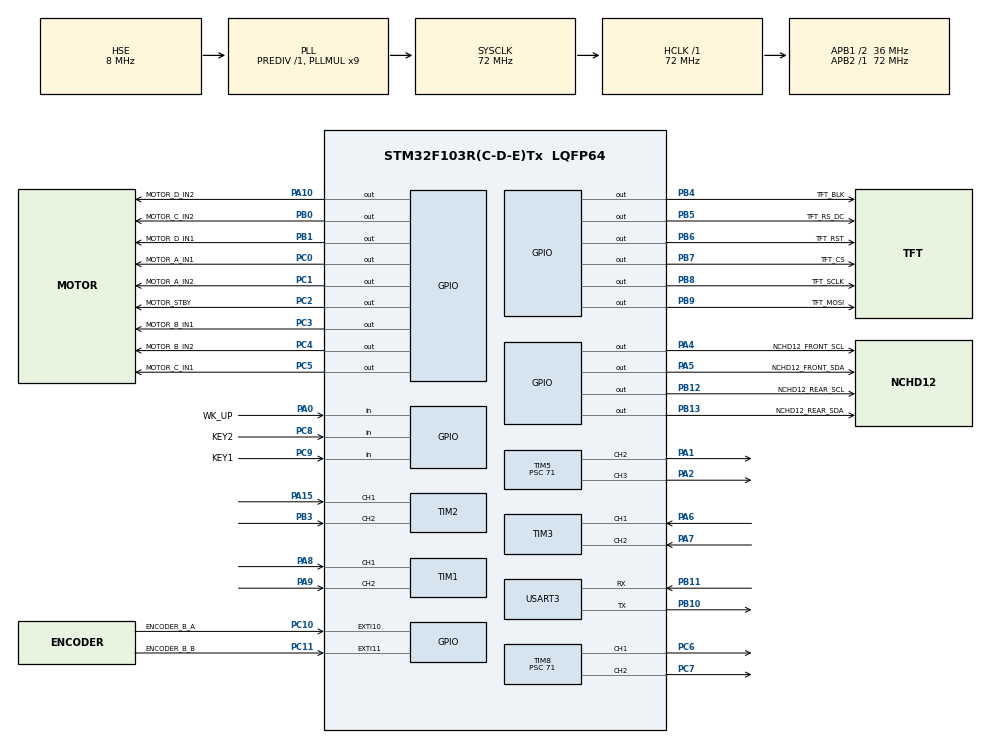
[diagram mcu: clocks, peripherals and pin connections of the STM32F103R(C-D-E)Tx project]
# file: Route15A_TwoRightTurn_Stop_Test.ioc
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Mcu.Family=STM32F1
Mcu.Name=STM32F103R(C-D-E)Tx
Mcu.Package=LQFP64
NVIC.EXTI15_10_IRQn=true\:5\:0\:false\:false\:true\:true\:true\:true
NVIC.PriorityGroup=NVIC_PRIORITYGROUP_4
PA0-WKUP.GPIO_Label=WK_UP
PA0-WKUP.GPIO_PuPd=GPIO_PULLDOWN
PA0-WKUP.Signal=GPIO_Input
PA1.Signal=S_TIM5_CH2
PA4.GPIO_Label=NCHD12_FRONT_SCL
PA4.Signal=GPIO_Output
PA5.GPIO_Label=NCHD12_FRONT_SDA
PA5.Signal=GPIO_Output
PA10.GPIO_Label=MOTOR_D_IN2
PA10.Signal=GPIO_Output
PA13.Mode=Serial_Wire
PA13.Signal=SYS_JTMS-SWDIO
PA14.Mode=Serial_Wire
PA14.Signal=SYS_JTCK-SWCLK
PA15.Signal=S_TIM2_CH1_ETR
PA2.Signal=S_TIM5_CH3
PA6.Signal=S_TIM3_CH1
PA7.Signal=S_TIM3_CH2
PA8.Signal=S_TIM1_CH1
PA9.Signal=S_TIM1_CH2
PB0.GPIO_Label=MOTOR_C_IN2
PB0.Signal=GPIO_Output
PB1.GPIO_Label=MOTOR_D_IN1
PB1.Signal=GPIO_Output
PB4.GPIO_Label=TFT_BLK
PB4.Signal=GPIO_Output
PB5.GPIO_Label=TFT_RS_DC
PB5.Signal=GPIO_Output
PB6.GPIO_Label=TFT_RST
PB6.Signal=GPIO_Output
PB7.GPIO_Label=TFT_CS
PB7.Signal=GPIO_Output
PB10.Mode=Asynchronous
PB10.Signal=USART3_TX
PB11.Mode=Asynchronous
PB11.Signal=USART3_RX
PB12.GPIO_Label=NCHD12_REAR_SCL
PB12.Signal=GPIO_Output
PB13.GPIO_Label=NCHD12_REAR_SDA
PB13.Signal=GPIO_Output
PB3.Signal=S_TIM2_CH2
PB8.GPIO_Label=TFT_SCLK
PB8.Signal=GPIO_Output
PB9.GPIO_Label=TFT_MOSI
PB9.Signal=GPIO_Output
PC10.GPIO_Label=ENCODER_B_A
PC10.GPIO_PuPd=GPIO_NOPULL
PC10.Signal=GPXTI10
PC11.GPIO_Label=ENCODER_B_B
PC11.GPIO_PuPd=GPIO_NOPULL
PC11.Signal=GPXTI11
PC0.GPIO_Label=MOTOR_A_IN1
PC0.Signal=GPIO_Output
PC1.GPIO_Label=MOTOR_A_IN2
PC1.Signal=GPIO_Output
PC2.GPIO_Label=MOTOR_STBY
PC2.Signal=GPIO_Output
PC3.GPIO_Label=MOTOR_B_IN1
PC3.Signal=GPIO_Output
PC4.GPIO_Label=MOTOR_B_IN2
PC4.Signal=GPIO_Output
PC5.GPIO_Label=MOTOR_C_IN1
PC5.Signal=GPIO_Output
PC6.Signal=S_TIM8_CH1
PC7.Signal=S_TIM8_CH2
PC8.GPIO_Label=KEY2
PC8.GPIO_PuPd=GPIO_PULLUP
PC8.Signal=GPIO_Input
PC9.GPIO_Label=KEY1
PC9.GPIO_PuPd=GPIO_PULLUP
PC9.Signal=GPIO_Input
PD0-OSC_IN.Mode=HSE-External-Oscillator
PD0-OSC_IN.Signal=RCC_OSC_IN
PD1-OSC_OUT.Mode=HSE-External-Oscillator
PD1-OSC_OUT.Signal=RCC_OSC_OUT
ProjectManager.HeapSize=0x200
ProjectManager.StackSize=0x400
ProjectManager.TargetToolchain=MDK-ARM V5.32
RCC.AHBFreq_Value=72000000
RCC.APB1CLKDivider=RCC_HCLK_DIV2
RCC.APB1Freq_Value=36000000
RCC.APB1TimFreq_Value=72000000
RCC.APB2Freq_Value=72000000
RCC.APB2TimFreq_Value=72000000
RCC.HCLKFreq_Value=72000000
RCC.PLLMUL=RCC_PLL_MUL9
RCC.PLLSourceVirtual=RCC_PLLSOURCE_HSE
RCC.SYSCLKFreq_VALUE=72000000
RCC.SYSCLKSource=RCC_SYSCLKSOURCE_PLLCLK
RCC.USBFreq_Value=72000000
SH.S_TIM1_CH1.0=TIM1_CH1,Encoder_Interface
SH.S_TIM1_CH2.0=TIM1_CH2,Encoder_Interface
SH.S_TIM2_CH1_ETR.0=TIM2_CH1,Encoder_Interface
SH.S_TIM2_CH2.0=TIM2_CH2,Encoder_Interface
SH.S_TIM3_CH1.0=TIM3_CH1,Encoder_Interface
SH.S_TIM3_CH2.0=TIM3_CH2,Encoder_Interface
SH.S_TIM5_CH2.0=TIM5_CH2,PWM Generation2 CH2
SH.S_TIM5_CH3.0=TIM5_CH3,PWM Generation3 CH3
SH.S_TIM8_CH1.0=TIM8_CH1,PWM Generation1 CH1
SH.S_TIM8_CH2.0=TIM8_CH2,PWM Generation2 CH2
TIM1.EncoderMode=TIM_ENCODERMODE_TI12
TIM2.EncoderMode=TIM_ENCODERMODE_TI12
TIM3.EncoderMode=TIM_ENCODERMODE_TI12
TIM5.AutoReloadPreload=TIM_AUTORELOAD_PRELOAD_ENABLE
TIM5.Channel-PWM\ Generation2\ CH2=TIM_CHANNEL_2
TIM5.Channel-PWM\ Generation3\ CH3=TIM_CHANNEL_3
TIM5.Period=999
TIM5.Prescaler=71
TIM8.AutoReloadPreload=TIM_AUTORELOAD_PRELOAD_ENABLE
TIM8.Channel-PWM\ Generation1\ CH1=TIM_CHANNEL_1
TIM8.Channel-PWM\ Generation2\ CH2=TIM_CHANNEL_2
TIM8.Period=999
TIM8.Prescaler=71
USART3.VirtualMode=VM_ASYNC
VP_TIM5_VS_ClockSourceINT.Mode=Internal
VP_TIM8_VS_ClockSourceINT.Mode=Internal
board=custom

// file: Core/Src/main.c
/* USER CODE BEGIN Header */
/**
  ******************************************************************************
  * @file           : main.c
  * @brief          : Main program body
  ******************************************************************************
  * @attention
  *
  * Copyright (c) 2026 STMicroelectronics.
  * All rights reserved.
  *
  * This software is licensed under terms that can be found in the LICENSE file
  * in the root directory of this software component.
  * If no LICENSE file comes with this software, it is provided AS-IS.
  *
  ******************************************************************************
  */
/* USER CODE END Header */
#include "main.h"

/* USER CODE BEGIN Includes */
#include "App_Route15A.h"

/* USER CODE END Includes */

TIM_HandleTypeDef htim1;
TIM_HandleTypeDef htim2;
TIM_HandleTypeDef htim3;
TIM_HandleTypeDef htim5;
TIM_HandleTypeDef htim8;

UART_HandleTypeDef huart3;

void SystemClock_Config(void);
static void MX_GPIO_Init(void);
static void MX_TIM1_Init(void);
static void MX_TIM3_Init(void);
static void MX_TIM2_Init(void);
static void MX_TIM5_Init(void);
static void MX_TIM8_Init(void);
static void MX_USART3_UART_Init(void);

int main(void)
{

  /* MCU Configuration--------------------------------------------------------*/

  /* Reset of all peripherals, Initializes the Flash interface and the Systick. */
  HAL_Init();

  /* Configure the system clock */
  SystemClock_Config();

  /* Initialize all configured peripherals */
  MX_GPIO_Init();
  MX_TIM1_Init();
  MX_TIM3_Init();
  MX_TIM2_Init();
  MX_TIM5_Init();
  MX_TIM8_Init();
  MX_USART3_UART_Init();
  /* USER CODE BEGIN 2 */
  App_Route15A_Init();

  /* USER CODE END 2 */

  /* Infinite loop */
  /* USER CODE BEGIN WHILE */
  while (1)
  {
    App_Route15A_Task();
    /* USER CODE END WHILE */

  }
}

void SystemClock_Config(void)
{
  RCC_OscInitTypeDef RCC_OscInitStruct = {0};
  RCC_ClkInitTypeDef RCC_ClkInitStruct = {0};

  /** Initializes the RCC Oscillators according to the specified parameters
  * in the RCC_OscInitTypeDef structure.
  */
  RCC_OscInitStruct.OscillatorType = RCC_OSCILLATORTYPE_HSE;
  RCC_OscInitStruct.HSEState = RCC_HSE_ON;
  RCC_OscInitStruct.HSEPredivValue = RCC_HSE_PREDIV_DIV1;
  RCC_OscInitStruct.HSIState = RCC_HSI_ON;
  RCC_OscInitStruct.PLL.PLLState = RCC_PLL_ON;
  RCC_OscInitStruct.PLL.PLLSource = RCC_PLLSOURCE_HSE;
  RCC_OscInitStruct.PLL.PLLMUL = RCC_PLL_MUL9;
  if (HAL_RCC_OscConfig(&RCC_OscInitStruct) != HAL_OK)
  {
    Error_Handler();
  }

  /** Initializes the CPU, AHB and APB buses clocks
  */
  RCC_ClkInitStruct.ClockType = RCC_CLOCKTYPE_HCLK|RCC_CLOCKTYPE_SYSCLK
                              |RCC_CLOCKTYPE_PCLK1|RCC_CLOCKTYPE_PCLK2;
  RCC_ClkInitStruct.SYSCLKSource = RCC_SYSCLKSOURCE_PLLCLK;
  RCC_ClkInitStruct.AHBCLKDivider = RCC_SYSCLK_DIV1;
  RCC_ClkInitStruct.APB1CLKDivider = RCC_HCLK_DIV2;
  RCC_ClkInitStruct.APB2CLKDivider = RCC_HCLK_DIV1;

  if (HAL_RCC_ClockConfig(&RCC_ClkInitStruct, FLASH_LATENCY_2) != HAL_OK)
  {
    Error_Handler();
  }
}

static void MX_TIM1_Init(void)
{

  TIM_Encoder_InitTypeDef sConfig = {0};
  TIM_MasterConfigTypeDef sMasterConfig = {0};

  htim1.Instance = TIM1;
  htim1.Init.Prescaler = 0;
  htim1.Init.CounterMode = TIM_COUNTERMODE_UP;
  htim1.Init.Period = 65535;
  htim1.Init.ClockDivision = TIM_CLOCKDIVISION_DIV1;
  htim1.Init.RepetitionCounter = 0;
  htim1.Init.AutoReloadPreload = TIM_AUTORELOAD_PRELOAD_DISABLE;
  sConfig.EncoderMode = TIM_ENCODERMODE_TI12;
  sConfig.IC1Polarity = TIM_ICPOLARITY_RISING;
  sConfig.IC1Selection = TIM_ICSELECTION_DIRECTTI;
  sConfig.IC1Prescaler = TIM_ICPSC_DIV1;
  sConfig.IC1Filter = 0;
  sConfig.IC2Polarity = TIM_ICPOLARITY_RISING;
  sConfig.IC2Selection = TIM_ICSELECTION_DIRECTTI;
  sConfig.IC2Prescaler = TIM_ICPSC_DIV1;
  sConfig.IC2Filter = 0;
  if (HAL_TIM_Encoder_Init(&htim1, &sConfig) != HAL_OK)
  {
    Error_Handler();
  }
  sMasterConfig.MasterOutputTrigger = TIM_TRGO_RESET;
  sMasterConfig.MasterSlaveMode = TIM_MASTERSLAVEMODE_DISABLE;
  if (HAL_TIMEx_MasterConfigSynchronization(&htim1, &sMasterConfig) != HAL_OK)
  {
    Error_Handler();
  }

}

static void MX_TIM2_Init(void)
{

  TIM_Encoder_InitTypeDef sConfig = {0};
  TIM_MasterConfigTypeDef sMasterConfig = {0};

  htim2.Instance = TIM2;
  htim2.Init.Prescaler = 0;
  htim2.Init.CounterMode = TIM_COUNTERMODE_UP;
  htim2.Init.Period = 65535;
  htim2.Init.ClockDivision = TIM_CLOCKDIVISION_DIV1;
  htim2.Init.AutoReloadPreload = TIM_AUTORELOAD_PRELOAD_DISABLE;
  sConfig.EncoderMode = TIM_ENCODERMODE_TI12;
  sConfig.IC1Polarity = TIM_ICPOLARITY_RISING;
  sConfig.IC1Selection = TIM_ICSELECTION_DIRECTTI;
  sConfig.IC1Prescaler = TIM_ICPSC_DIV1;
  sConfig.IC1Filter = 0;
  sConfig.IC2Polarity = TIM_ICPOLARITY_RISING;
  sConfig.IC2Selection = TIM_ICSELECTION_DIRECTTI;
  sConfig.IC2Prescaler = TIM_ICPSC_DIV1;
  sConfig.IC2Filter = 0;
  if (HAL_TIM_Encoder_Init(&htim2, &sConfig) != HAL_OK)
  {
    Error_Handler();
  }
  sMasterConfig.MasterOutputTrigger = TIM_TRGO_RESET;
  sMasterConfig.MasterSlaveMode = TIM_MASTERSLAVEMODE_DISABLE;
  if (HAL_TIMEx_MasterConfigSynchronization(&htim2, &sMasterConfig) != HAL_OK)
  {
    Error_Handler();
  }

}

static void MX_TIM3_Init(void)
{

  TIM_Encoder_InitTypeDef sConfig = {0};
  TIM_MasterConfigTypeDef sMasterConfig = {0};

  htim3.Instance = TIM3;
  htim3.Init.Prescaler = 0;
  htim3.Init.CounterMode = TIM_COUNTERMODE_UP;
  htim3.Init.Period = 65535;
  htim3.Init.ClockDivision = TIM_CLOCKDIVISION_DIV1;
  htim3.Init.AutoReloadPreload = TIM_AUTORELOAD_PRELOAD_DISABLE;
  sConfig.EncoderMode = TIM_ENCODERMODE_TI12;
  sConfig.IC1Polarity = TIM_ICPOLARITY_RISING;
  sConfig.IC1Selection = TIM_ICSELECTION_DIRECTTI;
  sConfig.IC1Prescaler = TIM_ICPSC_DIV1;
  sConfig.IC1Filter = 0;
  sConfig.IC2Polarity = TIM_ICPOLARITY_RISING;
  sConfig.IC2Selection = TIM_ICSELECTION_DIRECTTI;
  sConfig.IC2Prescaler = TIM_ICPSC_DIV1;
  sConfig.IC2Filter = 0;
  if (HAL_TIM_Encoder_Init(&htim3, &sConfig) != HAL_OK)
  {
    Error_Handler();
  }
  sMasterConfig.MasterOutputTrigger = TIM_TRGO_RESET;
  sMasterConfig.MasterSlaveMode = TIM_MASTERSLAVEMODE_DISABLE;
  if (HAL_TIMEx_MasterConfigSynchronization(&htim3, &sMasterConfig) != HAL_OK)
  {
    Error_Handler();
  }

}

static void MX_TIM5_Init(void)
{

  TIM_ClockConfigTypeDef sClockSourceConfig = {0};
  TIM_MasterConfigTypeDef sMasterConfig = {0};
  TIM_OC_InitTypeDef sConfigOC = {0};

  htim5.Instance = TIM5;
  htim5.Init.Prescaler = 71;
  htim5.Init.CounterMode = TIM_COUNTERMODE_UP;
  htim5.Init.Period = 999;
  htim5.Init.ClockDivision = TIM_CLOCKDIVISION_DIV1;
  htim5.Init.AutoReloadPreload = TIM_AUTORELOAD_PRELOAD_ENABLE;
  if (HAL_TIM_Base_Init(&htim5) != HAL_OK)
  {
    Error_Handler();
  }
  sClockSourceConfig.ClockSource = TIM_CLOCKSOURCE_INTERNAL;
  if (HAL_TIM_ConfigClockSource(&htim5, &sClockSourceConfig) != HAL_OK)
  {
    Error_Handler();
  }
  if (HAL_TIM_PWM_Init(&htim5) != HAL_OK)
  {
    Error_Handler();
  }
  sMasterConfig.MasterOutputTrigger = TIM_TRGO_RESET;
  sMasterConfig.MasterSlaveMode = TIM_MASTERSLAVEMODE_DISABLE;
  if (HAL_TIMEx_MasterConfigSynchronization(&htim5, &sMasterConfig) != HAL_OK)
  {
    Error_Handler();
  }
  sConfigOC.OCMode = TIM_OCMODE_PWM1;
  sConfigOC.Pulse = 0;
  sConfigOC.OCPolarity = TIM_OCPOLARITY_HIGH;
  sConfigOC.OCFastMode = TIM_OCFAST_DISABLE;
  if (HAL_TIM_PWM_ConfigChannel(&htim5, &sConfigOC, TIM_CHANNEL_2) != HAL_OK)
  {
    Error_Handler();
  }
  if (HAL_TIM_PWM_ConfigChannel(&htim5, &sConfigOC, TIM_CHANNEL_3) != HAL_OK)
  {
    Error_Handler();
  }
  HAL_TIM_MspPostInit(&htim5);

}

static void MX_TIM8_Init(void)
{

  TIM_ClockConfigTypeDef sClockSourceConfig = {0};
  TIM_MasterConfigTypeDef sMasterConfig = {0};
  TIM_OC_InitTypeDef sConfigOC = {0};
  TIM_BreakDeadTimeConfigTypeDef sBreakDeadTimeConfig = {0};

  htim8.Instance = TIM8;
  htim8.Init.Prescaler = 71;
  htim8.Init.CounterMode = TIM_COUNTERMODE_UP;
  htim8.Init.Period = 999;
  htim8.Init.ClockDivision = TIM_CLOCKDIVISION_DIV1;
  htim8.Init.RepetitionCounter = 0;
  htim8.Init.AutoReloadPreload = TIM_AUTORELOAD_PRELOAD_ENABLE;
  if (HAL_TIM_Base_Init(&htim8) != HAL_OK)
  {
    Error_Handler();
  }
  sClockSourceConfig.ClockSource = TIM_CLOCKSOURCE_INTERNAL;
  if (HAL_TIM_ConfigClockSource(&htim8, &sClockSourceConfig) != HAL_OK)
  {
    Error_Handler();
  }
  if (HAL_TIM_PWM_Init(&htim8) != HAL_OK)
  {
    Error_Handler();
  }
  sMasterConfig.MasterOutputTrigger = TIM_TRGO_RESET;
  sMasterConfig.MasterSlaveMode = TIM_MASTERSLAVEMODE_DISABLE;
  if (HAL_TIMEx_MasterConfigSynchronization(&htim8, &sMasterConfig) != HAL_OK)
  {
    Error_Handler();
  }
  sConfigOC.OCMode = TIM_OCMODE_PWM1;
  sConfigOC.Pulse = 0;
  sConfigOC.OCPolarity = TIM_OCPOLARITY_HIGH;
  sConfigOC.OCNPolarity = TIM_OCNPOLARITY_HIGH;
  sConfigOC.OCFastMode = TIM_OCFAST_DISABLE;
  sConfigOC.OCIdleState = TIM_OCIDLESTATE_RESET;
  sConfigOC.OCNIdleState = TIM_OCNIDLESTATE_RESET;
  if (HAL_TIM_PWM_ConfigChannel(&htim8, &sConfigOC, TIM_CHANNEL_1) != HAL_OK)
  {
    Error_Handler();
  }
  if (HAL_TIM_PWM_ConfigChannel(&htim8, &sConfigOC, TIM_CHANNEL_2) != HAL_OK)
  {
    Error_Handler();
  }
  sBreakDeadTimeConfig.OffStateRunMode = TIM_OSSR_DISABLE;
  sBreakDeadTimeConfig.OffStateIDLEMode = TIM_OSSI_DISABLE;
  sBreakDeadTimeConfig.LockLevel = TIM_LOCKLEVEL_OFF;
  sBreakDeadTimeConfig.DeadTime = 0;
  sBreakDeadTimeConfig.BreakState = TIM_BREAK_DISABLE;
  sBreakDeadTimeConfig.BreakPolarity = TIM_BREAKPOLARITY_HIGH;
  sBreakDeadTimeConfig.AutomaticOutput = TIM_AUTOMATICOUTPUT_DISABLE;
  if (HAL_TIMEx_ConfigBreakDeadTime(&htim8, &sBreakDeadTimeConfig) != HAL_OK)
  {
    Error_Handler();
  }
  HAL_TIM_MspPostInit(&htim8);

}

static void MX_USART3_UART_Init(void)
{

  huart3.Instance = USART3;
  huart3.Init.BaudRate = 115200;
  huart3.Init.WordLength = UART_WORDLENGTH_8B;
  huart3.Init.StopBits = UART_STOPBITS_1;
  huart3.Init.Parity = UART_PARITY_NONE;
  huart3.Init.Mode = UART_MODE_TX_RX;
  huart3.Init.HwFlowCtl = UART_HWCONTROL_NONE;
  huart3.Init.OverSampling = UART_OVERSAMPLING_16;
  if (HAL_UART_Init(&huart3) != HAL_OK)
  {
    Error_Handler();
  }

}

static void MX_GPIO_Init(void)
{
  GPIO_InitTypeDef GPIO_InitStruct = {0};

  /* GPIO Ports Clock Enable */
  __HAL_RCC_GPIOD_CLK_ENABLE();
  __HAL_RCC_GPIOC_CLK_ENABLE();
  __HAL_RCC_GPIOA_CLK_ENABLE();
  __HAL_RCC_GPIOB_CLK_ENABLE();

  /*Configure GPIO pin Output Level */
  HAL_GPIO_WritePin(GPIOC, MOTOR_A_IN1_Pin|MOTOR_A_IN2_Pin|MOTOR_STBY_Pin|MOTOR_B_IN1_Pin
                          |MOTOR_B_IN2_Pin|MOTOR_C_IN1_Pin, GPIO_PIN_RESET);

  /*Configure GPIO pin Output Level */
  HAL_GPIO_WritePin(GPIOB, MOTOR_C_IN2_Pin|MOTOR_D_IN1_Pin, GPIO_PIN_RESET);

  /*Configure GPIO pin Output Level */
  HAL_GPIO_WritePin(MOTOR_D_IN2_GPIO_Port, MOTOR_D_IN2_Pin, GPIO_PIN_RESET);

  /*Configure GPIO pin Output Level */
  HAL_GPIO_WritePin(GPIOB,
                   TFT_BLK_Pin | TFT_RS_DC_Pin | TFT_RST_Pin |
                   TFT_CS_Pin | TFT_SCLK_Pin | TFT_MOSI_Pin,
                   GPIO_PIN_RESET);

  /* Configure the front software-I2C bus released high. */
  HAL_GPIO_WritePin(GPIOA,
                   NCHD12_FRONT_SCL_Pin | NCHD12_FRONT_SDA_Pin,
                   GPIO_PIN_SET);

  /*Configure GPIO pins : MOTOR_A_IN1_Pin MOTOR_A_IN2_Pin MOTOR_STBY_Pin MOTOR_B_IN1_Pin
                           MOTOR_B_IN2_Pin MOTOR_C_IN1_Pin */
  GPIO_InitStruct.Pin = MOTOR_A_IN1_Pin|MOTOR_A_IN2_Pin|MOTOR_STBY_Pin|MOTOR_B_IN1_Pin
                          |MOTOR_B_IN2_Pin|MOTOR_C_IN1_Pin;
  GPIO_InitStruct.Mode = GPIO_MODE_OUTPUT_PP;
  GPIO_InitStruct.Pull = GPIO_NOPULL;
  GPIO_InitStruct.Speed = GPIO_SPEED_FREQ_LOW;
  HAL_GPIO_Init(GPIOC, &GPIO_InitStruct);

  /*Configure GPIO pin : WK_UP_Pin */
  GPIO_InitStruct.Pin = WK_UP_Pin;
  GPIO_InitStruct.Mode = GPIO_MODE_INPUT;
  GPIO_InitStruct.Pull = GPIO_PULLDOWN;
  HAL_GPIO_Init(WK_UP_GPIO_Port, &GPIO_InitStruct);

  /*Configure GPIO pins : MOTOR_C_IN2_Pin MOTOR_D_IN1_Pin */
  GPIO_InitStruct.Pin = MOTOR_C_IN2_Pin|MOTOR_D_IN1_Pin;
  GPIO_InitStruct.Mode = GPIO_MODE_OUTPUT_PP;
  GPIO_InitStruct.Pull = GPIO_NOPULL;
  GPIO_InitStruct.Speed = GPIO_SPEED_FREQ_LOW;
  HAL_GPIO_Init(GPIOB, &GPIO_InitStruct);

  /*Configure GPIO pins : KEY2_Pin KEY1_Pin */
  GPIO_InitStruct.Pin = KEY2_Pin|KEY1_Pin;
  GPIO_InitStruct.Mode = GPIO_MODE_INPUT;
  GPIO_InitStruct.Pull = GPIO_PULLUP;
  HAL_GPIO_Init(GPIOC, &GPIO_InitStruct);

  /*Configure GPIO pin : MOTOR_D_IN2_Pin */
  GPIO_InitStruct.Pin = MOTOR_D_IN2_Pin;
  GPIO_InitStruct.Mode = GPIO_MODE_OUTPUT_PP;
  GPIO_InitStruct.Pull = GPIO_NOPULL;
  GPIO_InitStruct.Speed = GPIO_SPEED_FREQ_LOW;
  HAL_GPIO_Init(MOTOR_D_IN2_GPIO_Port, &GPIO_InitStruct);

  /* Configure the front NCHD12 software-I2C pins. */
  GPIO_InitStruct.Pin = NCHD12_FRONT_SCL_Pin | NCHD12_FRONT_SDA_Pin;
  GPIO_InitStruct.Mode = GPIO_MODE_OUTPUT_OD;
  GPIO_InitStruct.Pull = GPIO_PULLUP;
  GPIO_InitStruct.Speed = GPIO_SPEED_FREQ_HIGH;
  HAL_GPIO_Init(NCHD12_FRONT_SCL_GPIO_Port, &GPIO_InitStruct);

  /* Configure the TFT fixed-interface pins. */
  GPIO_InitStruct.Pin = TFT_BLK_Pin | TFT_RS_DC_Pin | TFT_RST_Pin |
                        TFT_CS_Pin | TFT_SCLK_Pin | TFT_MOSI_Pin;
  GPIO_InitStruct.Mode = GPIO_MODE_OUTPUT_PP;
  GPIO_InitStruct.Pull = GPIO_NOPULL;
  GPIO_InitStruct.Speed = GPIO_SPEED_FREQ_HIGH;
  HAL_GPIO_Init(TFT_BLK_GPIO_Port, &GPIO_InitStruct);

  /* Configure encoder B for software quadrature decoding. */
  GPIO_InitStruct.Pin = ENCODER_B_A_Pin | ENCODER_B_B_Pin;
  GPIO_InitStruct.Mode = GPIO_MODE_IT_RISING_FALLING;
  GPIO_InitStruct.Pull = GPIO_NOPULL;
  HAL_GPIO_Init(ENCODER_B_A_GPIO_Port, &GPIO_InitStruct);

  HAL_NVIC_SetPriority(EXTI15_10_IRQn, 5, 0);
  HAL_NVIC_EnableIRQ(EXTI15_10_IRQn);

}

void Error_Handler(void)
{
  __disable_irq();
  while (1)
  {
  }
}
